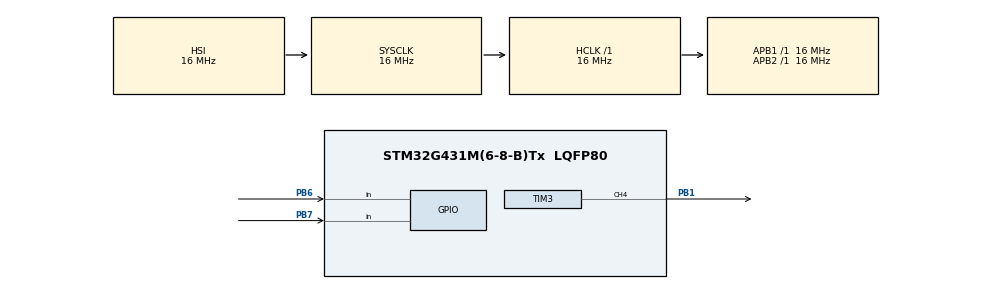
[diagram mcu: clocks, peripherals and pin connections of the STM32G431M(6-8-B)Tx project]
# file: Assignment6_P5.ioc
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Mcu.Family=STM32G4
Mcu.Name=STM32G431M(6-8-B)Tx
Mcu.Package=LQFP80
NVIC.PriorityGroup=NVIC_PRIORITYGROUP_4
PA13.Mode=Serial_Wire
PA13.Signal=SYS_JTMS-SWDIO
PA14.Mode=Serial_Wire
PA14.Signal=SYS_JTCK-SWCLK
PB1.GPIO_PuPd=GPIO_NOPULL
PB1.Signal=S_TIM3_CH4
PB6.GPIO_PuPd=GPIO_PULLUP
PB6.Signal=GPIO_Input
PB7.GPIO_PuPd=GPIO_PULLUP
PB7.Signal=GPIO_Input
ProjectManager.HeapSize=0x200
ProjectManager.StackSize=0x400
ProjectManager.TargetToolchain=STM32CubeIDE
RCC.AHBFreq_Value=16000000
RCC.APB1Freq_Value=16000000
RCC.APB1TimFreq_Value=16000000
RCC.APB2Freq_Value=16000000
RCC.APB2TimFreq_Value=16000000
RCC.CortexFreq_Value=16000000
RCC.EXTERNAL_CLOCK_VALUE=12288000
RCC.HCLKFreq_Value=16000000
RCC.HSE_VALUE=8000000
RCC.HSI48_VALUE=48000000
RCC.HSI_VALUE=16000000
RCC.LSE_VALUE=32768
RCC.SYSCLKFreq_VALUE=16000000
RCC.USBFreq_Value=64000000
RCC.VCOOutputFreq_Value=128000000
SH.S_TIM3_CH4.0=TIM3_CH4,PWM Generation4 CH4
TIM3.Channel-PWM\ Generation4\ CH4=TIM_CHANNEL_4
TIM3.Prescaler=0
VP_SYS_VS_DBSignals.Mode=DisableDeadBatterySignals
VP_TIM3_VS_ClockSourceINT.Mode=Internal
board=custom

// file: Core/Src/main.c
/* USER CODE BEGIN Header */
/**
  ******************************************************************************
  * @file           : main.c
  * @brief          : Main program body
  ******************************************************************************
  * @attention
  *
  * Copyright (c) 2025 STMicroelectronics.
  * All rights reserved.
  *
  * This software is licensed under terms that can be found in the LICENSE file
  * in the root directory of this software component.
  * If no LICENSE file comes with this software, it is provided AS-IS.
  *
  ******************************************************************************
  */
/* USER CODE END Header */
#include "main.h"

TIM_HandleTypeDef htim3;

void SystemClock_Config(void);
static void MX_GPIO_Init(void);
static void MX_TIM3_Init(void);

int main(void)
{

  /* MCU Configuration--------------------------------------------------------*/

  /* Reset of all peripherals, Initializes the Flash interface and the Systick. */
  HAL_Init();

  /* Configure the system clock */
  SystemClock_Config();

  /* Initialize all configured peripherals */
  MX_GPIO_Init();
  MX_TIM3_Init();
  /* USER CODE BEGIN 2 */

  //initializing brightness (Highest number, lower the LED brightness)
  uint16_t brightness = 65535;

  //Starts PWM with TIM2 channel 4
  HAL_TIM_PWM_Start(&htim3, TIM_CHANNEL_4);

  //Sets PWM with value of brightness (default LED OFF)
  __HAL_TIM_SET_COMPARE(&htim3, TIM_CHANNEL_4, brightness);
  /* USER CODE END 2 */

  /* Infinite loop */
  /* USER CODE BEGIN WHILE */
  while (1)
  {
	  //each press of a pushbutton 1 increases LED brightness
	  if((HAL_GPIO_ReadPin(GPIOB, GPIO_PIN_7)) == 0) //checks if button 1 is pressed
	  {
		  //condition to check and limit MAX brightness
		  if (brightness >10000){
			  brightness -= 10000; // Increases LED brightness
			  __HAL_TIM_SET_COMPARE(&htim3, TIM_CHANNEL_4, brightness); // Sets LED brightness
		  }
		  // Sets MAX brightness
		  else{
			  brightness = 0;
			  __HAL_TIM_SET_COMPARE(&htim3, TIM_CHANNEL_4, brightness);
		  }
	  }

	  //each press of a pushbutton 2 decreases LED brightness.
	  if((HAL_GPIO_ReadPin(GPIOB, GPIO_PIN_6)) == 0) //checks if button 2 is pressed
	  {
		  //condition to check and limit Lowest brightness
		  if(brightness < 55535){
			  brightness += 10000; //Decreases LED brightness
			  __HAL_TIM_SET_COMPARE(&htim3, TIM_CHANNEL_4, brightness); //Sets LED brightness
		  }

		  // Sets Lowest brightness
		  else{
			  brightness = 65535;
			  __HAL_TIM_SET_COMPARE(&htim3, TIM_CHANNEL_4, brightness);

		  }
	  }

	  HAL_Delay(500); //Delay of 0.5 Sec
    /* USER CODE END WHILE */

  }
}

void SystemClock_Config(void)
{
  RCC_OscInitTypeDef RCC_OscInitStruct = {0};
  RCC_ClkInitTypeDef RCC_ClkInitStruct = {0};

  /** Configure the main internal regulator output voltage
  */
  HAL_PWREx_ControlVoltageScaling(PWR_REGULATOR_VOLTAGE_SCALE1);

  /** Initializes the RCC Oscillators according to the specified parameters
  * in the RCC_OscInitTypeDef structure.
  */
  RCC_OscInitStruct.OscillatorType = RCC_OSCILLATORTYPE_HSI;
  RCC_OscInitStruct.HSIState = RCC_HSI_ON;
  RCC_OscInitStruct.HSICalibrationValue = RCC_HSICALIBRATION_DEFAULT;
  RCC_OscInitStruct.PLL.PLLState = RCC_PLL_NONE;
  if (HAL_RCC_OscConfig(&RCC_OscInitStruct) != HAL_OK)
  {
    Error_Handler();
  }

  /** Initializes the CPU, AHB and APB buses clocks
  */
  RCC_ClkInitStruct.ClockType = RCC_CLOCKTYPE_HCLK|RCC_CLOCKTYPE_SYSCLK
                              |RCC_CLOCKTYPE_PCLK1|RCC_CLOCKTYPE_PCLK2;
  RCC_ClkInitStruct.SYSCLKSource = RCC_SYSCLKSOURCE_HSI;
  RCC_ClkInitStruct.AHBCLKDivider = RCC_SYSCLK_DIV1;
  RCC_ClkInitStruct.APB1CLKDivider = RCC_HCLK_DIV1;
  RCC_ClkInitStruct.APB2CLKDivider = RCC_HCLK_DIV1;

  if (HAL_RCC_ClockConfig(&RCC_ClkInitStruct, FLASH_LATENCY_0) != HAL_OK)
  {
    Error_Handler();
  }
}

static void MX_TIM3_Init(void)
{

  TIM_ClockConfigTypeDef sClockSourceConfig = {0};
  TIM_MasterConfigTypeDef sMasterConfig = {0};
  TIM_OC_InitTypeDef sConfigOC = {0};

  htim3.Instance = TIM3;
  htim3.Init.Prescaler = 0;
  htim3.Init.CounterMode = TIM_COUNTERMODE_UP;
  htim3.Init.Period = 65535;
  htim3.Init.ClockDivision = TIM_CLOCKDIVISION_DIV1;
  htim3.Init.AutoReloadPreload = TIM_AUTORELOAD_PRELOAD_DISABLE;
  if (HAL_TIM_Base_Init(&htim3) != HAL_OK)
  {
    Error_Handler();
  }
  sClockSourceConfig.ClockSource = TIM_CLOCKSOURCE_INTERNAL;
  if (HAL_TIM_ConfigClockSource(&htim3, &sClockSourceConfig) != HAL_OK)
  {
    Error_Handler();
  }
  if (HAL_TIM_PWM_Init(&htim3) != HAL_OK)
  {
    Error_Handler();
  }
  sMasterConfig.MasterOutputTrigger = TIM_TRGO_RESET;
  sMasterConfig.MasterSlaveMode = TIM_MASTERSLAVEMODE_DISABLE;
  if (HAL_TIMEx_MasterConfigSynchronization(&htim3, &sMasterConfig) != HAL_OK)
  {
    Error_Handler();
  }
  sConfigOC.OCMode = TIM_OCMODE_PWM1;
  sConfigOC.Pulse = 0;
  sConfigOC.OCPolarity = TIM_OCPOLARITY_HIGH;
  sConfigOC.OCFastMode = TIM_OCFAST_DISABLE;
  if (HAL_TIM_PWM_ConfigChannel(&htim3, &sConfigOC, TIM_CHANNEL_4) != HAL_OK)
  {
    Error_Handler();
  }
  HAL_TIM_MspPostInit(&htim3);

}

static void MX_GPIO_Init(void)
{
  GPIO_InitTypeDef GPIO_InitStruct = {0};

  /* GPIO Ports Clock Enable */
  __HAL_RCC_GPIOB_CLK_ENABLE();
  __HAL_RCC_GPIOA_CLK_ENABLE();

  /*Configure GPIO pins : PB6 PB7 */
  GPIO_InitStruct.Pin = GPIO_PIN_6|GPIO_PIN_7;
  GPIO_InitStruct.Mode = GPIO_MODE_INPUT;
  GPIO_InitStruct.Pull = GPIO_PULLUP;
  HAL_GPIO_Init(GPIOB, &GPIO_InitStruct);

}

void Error_Handler(void)
{
  __disable_irq();
  while (1)
  {
  }
}
